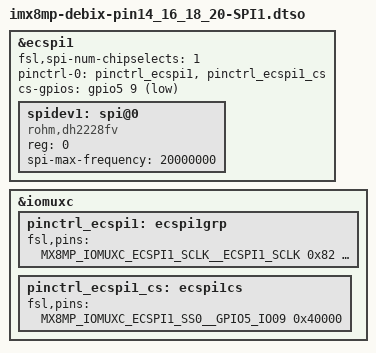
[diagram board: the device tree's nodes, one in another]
/dts-v1/;
/plugin/;

#include "imx8mp-pinfunc.h"
#include <dt-bindings/gpio/gpio.h>

&ecspi1 {
	#address-cells = <1>;
	#size-cells = <0>;
	fsl,spi-num-chipselects = <1>;
	pinctrl-names = "default";
	pinctrl-0 = <&pinctrl_ecspi1 &pinctrl_ecspi1_cs>;
	cs-gpios = <&gpio5 9 GPIO_ACTIVE_LOW>;
	status = "okay";
	spidev1: spi@0 {
		reg = <0>;
		compatible = "rohm,dh2228fv";
		spi-max-frequency = <20000000>;
	};
};

&iomuxc {
	pinctrl_ecspi1: ecspi1grp {
		fsl,pins = <
			MX8MP_IOMUXC_ECSPI1_SCLK__ECSPI1_SCLK		0x82
			MX8MP_IOMUXC_ECSPI1_MOSI__ECSPI1_MOSI		0x82
			MX8MP_IOMUXC_ECSPI1_MISO__ECSPI1_MISO		0x82
		>;
	};
	

	pinctrl_ecspi1_cs: ecspi1cs {
		fsl,pins = <
			MX8MP_IOMUXC_ECSPI1_SS0__GPIO5_IO09		0x40000
		>;
	};
};

